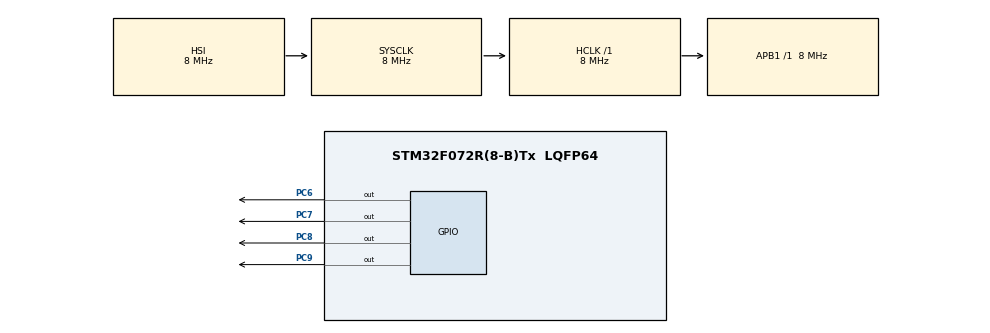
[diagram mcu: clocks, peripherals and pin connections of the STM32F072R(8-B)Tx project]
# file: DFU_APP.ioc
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Mcu.Family=STM32F0
Mcu.Name=STM32F072R(8-B)Tx
Mcu.Package=LQFP64
PA13.Mode=Serial_Wire
PA13.Signal=SYS_SWDIO
PA14.Mode=Serial_Wire
PA14.Signal=SYS_SWCLK
PC6.Signal=GPIO_Output
PC7.Signal=GPIO_Output
PC8.Signal=GPIO_Output
PC9.Signal=GPIO_Output
ProjectManager.HeapSize=0x200
ProjectManager.StackSize=0x400
ProjectManager.TargetToolchain=MDK-ARM V5
RCC.AHBFreq_Value=8000000
RCC.APB1Freq_Value=8000000
RCC.APB1TimFreq_Value=8000000
RCC.HCLKFreq_Value=8000000
RCC.SYSCLKFreq_VALUE=8000000
board=custom

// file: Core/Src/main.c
/* USER CODE BEGIN Header */
/**
  ******************************************************************************
  * @file           : main.c
  * @brief          : Main program body
  ******************************************************************************
  * @attention
  *
  * <h2><center>&copy; Copyright (c) 2020 STMicroelectronics.
  * All rights reserved.</center></h2>
  *
  * This software component is licensed by ST under BSD 3-Clause license,
  * the "License"; You may not use this file except in compliance with the
  * License. You may obtain a copy of the License at:
  *                        opensource.org/licenses/BSD-3-Clause
  *
  ******************************************************************************
  */
/* USER CODE END Header */

#include "main.h"
#include "gpio.h"

void SystemClock_Config(void);

int main(void)
{
  /* USER CODE BEGIN 1 */
  HAL_FLASH_Unlock();
  for(uint8_t i = 0; i < 48; i++)
  {
    *((uint32_t*)(0x20000000 + (i << 2)))=*(__IO uint32_t*)(0x08007000 + (i<<2));
  }
	HAL_FLASH_Lock();
	__HAL_RCC_SYSCFG_IS_CLK_ENABLED();
  __HAL_SYSCFG_REMAPMEMORY_SRAM();
  /* USER CODE END 1 */

  /* MCU Configuration--------------------------------------------------------*/

  /* Reset of all peripherals, Initializes the Flash interface and the Systick. */
  HAL_Init();

  /* Configure the system clock */
  SystemClock_Config();

  /* Initialize all configured peripherals */
  MX_GPIO_Init();

  /* Infinite loop */
  while (1)
  {

    /* USER CODE BEGIN 3 */
		HAL_GPIO_WritePin(GPIOC, GPIO_PIN_6|GPIO_PIN_7|GPIO_PIN_8|GPIO_PIN_9, GPIO_PIN_SET);
		HAL_Delay(500);
		HAL_GPIO_WritePin(GPIOC, GPIO_PIN_6|GPIO_PIN_7|GPIO_PIN_8|GPIO_PIN_9, GPIO_PIN_RESET);
		HAL_Delay(500);
  }
  /* USER CODE END 3 */
}

void SystemClock_Config(void)
{
  RCC_OscInitTypeDef RCC_OscInitStruct = {0};
  RCC_ClkInitTypeDef RCC_ClkInitStruct = {0};

  /** Initializes the CPU, AHB and APB busses clocks
  */
  RCC_OscInitStruct.OscillatorType = RCC_OSCILLATORTYPE_HSI;
  RCC_OscInitStruct.HSIState = RCC_HSI_ON;
  RCC_OscInitStruct.HSICalibrationValue = RCC_HSICALIBRATION_DEFAULT;
  RCC_OscInitStruct.PLL.PLLState = RCC_PLL_NONE;
  if (HAL_RCC_OscConfig(&RCC_OscInitStruct) != HAL_OK)
  {
    Error_Handler();
  }
  /** Initializes the CPU, AHB and APB busses clocks
  */
  RCC_ClkInitStruct.ClockType = RCC_CLOCKTYPE_HCLK|RCC_CLOCKTYPE_SYSCLK
                              |RCC_CLOCKTYPE_PCLK1;
  RCC_ClkInitStruct.SYSCLKSource = RCC_SYSCLKSOURCE_HSI;
  RCC_ClkInitStruct.AHBCLKDivider = RCC_SYSCLK_DIV1;
  RCC_ClkInitStruct.APB1CLKDivider = RCC_HCLK_DIV1;

  if (HAL_RCC_ClockConfig(&RCC_ClkInitStruct, FLASH_LATENCY_0) != HAL_OK)
  {
    Error_Handler();
  }
}

void Error_Handler(void)
{
}

/************************ (C) COPYRIGHT STMicroelectronics *****END OF FILE****/
